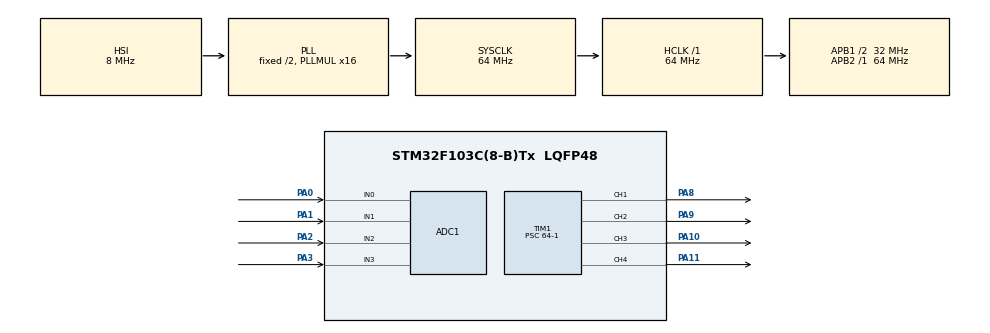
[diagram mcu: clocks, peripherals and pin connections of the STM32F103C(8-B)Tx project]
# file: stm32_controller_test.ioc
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ADC1.Channel-0\#ChannelRegularConversion=ADC_CHANNEL_0
ADC1.Channel-1\#ChannelRegularConversion=ADC_CHANNEL_1
ADC1.Channel-2\#ChannelRegularConversion=ADC_CHANNEL_2
ADC1.Channel-3\#ChannelRegularConversion=ADC_CHANNEL_3
ADC1.NbrOfConversion=4
ADC1.NbrOfConversionFlag=1
ADC1.Rank-0\#ChannelRegularConversion=1
ADC1.Rank-1\#ChannelRegularConversion=2
ADC1.Rank-2\#ChannelRegularConversion=3
ADC1.Rank-3\#ChannelRegularConversion=4
ADC1.SamplingTime-0\#ChannelRegularConversion=ADC_SAMPLETIME_1CYCLE_5
ADC1.SamplingTime-1\#ChannelRegularConversion=ADC_SAMPLETIME_1CYCLE_5
ADC1.SamplingTime-2\#ChannelRegularConversion=ADC_SAMPLETIME_1CYCLE_5
ADC1.SamplingTime-3\#ChannelRegularConversion=ADC_SAMPLETIME_1CYCLE_5
ADC1.master=1
Dma.ADC1.0.Direction=DMA_PERIPH_TO_MEMORY
Dma.ADC1.0.Instance=DMA1_Channel1
Dma.ADC1.0.MemDataAlignment=DMA_MDATAALIGN_HALFWORD
Dma.ADC1.0.MemInc=DMA_MINC_ENABLE
Dma.ADC1.0.Mode=DMA_CIRCULAR
Dma.ADC1.0.PeriphDataAlignment=DMA_PDATAALIGN_HALFWORD
Dma.ADC1.0.PeriphInc=DMA_PINC_DISABLE
Dma.ADC1.0.Priority=DMA_PRIORITY_LOW
Dma.Request0=ADC1
Mcu.Family=STM32F1
Mcu.Name=STM32F103C(8-B)Tx
Mcu.Package=LQFP48
NVIC.DMA1_Channel1_IRQn=true\:0\:0\:false\:false\:true\:false\:true\:true
NVIC.PriorityGroup=NVIC_PRIORITYGROUP_4
PA0-WKUP.Signal=ADCx_IN0
PA1.Signal=ADCx_IN1
PA10.Signal=S_TIM1_CH3
PA11.Signal=S_TIM1_CH4
PA13.Mode=Serial_Wire
PA13.Signal=SYS_JTMS-SWDIO
PA14.Mode=Serial_Wire
PA14.Signal=SYS_JTCK-SWCLK
PA2.Signal=ADCx_IN2
PA3.Signal=ADCx_IN3
PA8.Signal=S_TIM1_CH1
PA9.Signal=S_TIM1_CH2
ProjectManager.HeapSize=0x200
ProjectManager.StackSize=0x400
ProjectManager.TargetToolchain=MDK-ARM V5.32
RCC.ADCPresc=RCC_ADCPCLK2_DIV8
RCC.AHBFreq_Value=64000000
RCC.APB1CLKDivider=RCC_HCLK_DIV2
RCC.APB1Freq_Value=32000000
RCC.APB1TimFreq_Value=64000000
RCC.APB2Freq_Value=64000000
RCC.APB2TimFreq_Value=64000000
RCC.HCLKFreq_Value=64000000
RCC.PLLMUL=RCC_PLL_MUL16
RCC.SYSCLKFreq_VALUE=64000000
RCC.SYSCLKSource=RCC_SYSCLKSOURCE_PLLCLK
RCC.USBFreq_Value=64000000
SH.ADCx_IN0.0=ADC1_IN0,IN0
SH.ADCx_IN1.0=ADC1_IN1,IN1
SH.ADCx_IN2.0=ADC1_IN2,IN2
SH.ADCx_IN3.0=ADC1_IN3,IN3
SH.S_TIM1_CH1.0=TIM1_CH1,PWM Generation1 CH1
SH.S_TIM1_CH2.0=TIM1_CH2,PWM Generation2 CH2
SH.S_TIM1_CH3.0=TIM1_CH3,PWM Generation3 CH3
SH.S_TIM1_CH4.0=TIM1_CH4,PWM Generation4 CH4
TIM1.Channel-PWM\ Generation1\ CH1=TIM_CHANNEL_1
TIM1.Channel-PWM\ Generation2\ CH2=TIM_CHANNEL_2
TIM1.Channel-PWM\ Generation3\ CH3=TIM_CHANNEL_3
TIM1.Channel-PWM\ Generation4\ CH4=TIM_CHANNEL_4
TIM1.Prescaler=64-1
VP_TIM1_VS_ClockSourceINT.Mode=Internal
board=custom

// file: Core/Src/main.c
/* USER CODE BEGIN Header */
/**
  ******************************************************************************
  * @file           : main.c
  * @brief          : Main program body
  ******************************************************************************
  * @attention
  *
  * Copyright (c) 2025 STMicroelectronics.
  * All rights reserved.
  *
  * This software is licensed under terms that can be found in the LICENSE file
  * in the root directory of this software component.
  * If no LICENSE file comes with this software, it is provided AS-IS.
  *
  ******************************************************************************
  */
/* USER CODE END Header */
#include "main.h"

ADC_HandleTypeDef hadc1;
DMA_HandleTypeDef hdma_adc1;

TIM_HandleTypeDef htim1;

void SystemClock_Config(void);
static void MX_GPIO_Init(void);
static void MX_DMA_Init(void);
static void MX_ADC1_Init(void);
static void MX_TIM1_Init(void);

/* USER CODE BEGIN 0 */
#define ADC_BUFF_LEN 4
uint16_t adc_buffer[ADC_BUFF_LEN];

extern ADC_HandleTypeDef hadc1;
extern TIM_HandleTypeDef htim2;

void HAL_ADC_ConvCpltCallback(ADC_HandleTypeDef* hadc) {
    // Callback không c?n thi?t khi dùng Circular, x? lý ? while(1)
}

void read_controller_start() {
		HAL_ADCEx_Calibration_Start(&hadc1);
    HAL_ADC_Start_DMA(&hadc1, (uint32_t*)adc_buffer, ADC_BUFF_LEN);
    HAL_TIM_PWM_Start(&htim1, TIM_CHANNEL_1); // B?t d?u PWM
    // L?p n?u b?n dùng thêm TIM_CHANNEL_2,3,4
}
/* USER CODE END 0 */

int main(void)
{

  /* MCU Configuration--------------------------------------------------------*/

  /* Reset of all peripherals, Initializes the Flash interface and the Systick. */
  HAL_Init();

  /* Configure the system clock */
  SystemClock_Config();

  /* Initialize all configured peripherals */
  MX_GPIO_Init();
  MX_DMA_Init();
  MX_ADC1_Init();
  MX_TIM1_Init();
  /* USER CODE BEGIN 2 */
	read_controller_start();
  /* USER CODE END 2 */

  /* Infinite loop */
  while (1)
  {

    uint16_t ch1 = adc_buffer[0];
		uint16_t ch2 = adc_buffer[1];
		uint16_t ch3 = adc_buffer[2];
		uint16_t ch4 = adc_buffer[3];

    uint16_t pwm_ch1 = 1000 + ((ch1 * 1000) / 4095);
		uint16_t pwm_ch2 = 1000 + ((ch2 * 1000) / 4095);
		uint16_t pwm_ch3 = 1000 + ((ch3 * 1000) / 4095);
		uint16_t pwm_ch4 = 1000 + ((ch4 * 1000) / 4095);

    __HAL_TIM_SET_COMPARE(&htim1, TIM_CHANNEL_1, pwm_ch1);
		__HAL_TIM_SET_COMPARE(&htim1, TIM_CHANNEL_2, pwm_ch2);
		__HAL_TIM_SET_COMPARE(&htim1, TIM_CHANNEL_3, pwm_ch3);
		__HAL_TIM_SET_COMPARE(&htim1, TIM_CHANNEL_4, pwm_ch4);

  }
}

void SystemClock_Config(void)
{
  RCC_OscInitTypeDef RCC_OscInitStruct = {0};
  RCC_ClkInitTypeDef RCC_ClkInitStruct = {0};
  RCC_PeriphCLKInitTypeDef PeriphClkInit = {0};

  /** Initializes the RCC Oscillators according to the specified parameters
  * in the RCC_OscInitTypeDef structure.
  */
  RCC_OscInitStruct.OscillatorType = RCC_OSCILLATORTYPE_HSI;
  RCC_OscInitStruct.HSIState = RCC_HSI_ON;
  RCC_OscInitStruct.HSICalibrationValue = RCC_HSICALIBRATION_DEFAULT;
  RCC_OscInitStruct.PLL.PLLState = RCC_PLL_ON;
  RCC_OscInitStruct.PLL.PLLSource = RCC_PLLSOURCE_HSI_DIV2;
  RCC_OscInitStruct.PLL.PLLMUL = RCC_PLL_MUL16;
  if (HAL_RCC_OscConfig(&RCC_OscInitStruct) != HAL_OK)
  {
    Error_Handler();
  }

  /** Initializes the CPU, AHB and APB buses clocks
  */
  RCC_ClkInitStruct.ClockType = RCC_CLOCKTYPE_HCLK|RCC_CLOCKTYPE_SYSCLK
                              |RCC_CLOCKTYPE_PCLK1|RCC_CLOCKTYPE_PCLK2;
  RCC_ClkInitStruct.SYSCLKSource = RCC_SYSCLKSOURCE_PLLCLK;
  RCC_ClkInitStruct.AHBCLKDivider = RCC_SYSCLK_DIV1;
  RCC_ClkInitStruct.APB1CLKDivider = RCC_HCLK_DIV2;
  RCC_ClkInitStruct.APB2CLKDivider = RCC_HCLK_DIV1;

  if (HAL_RCC_ClockConfig(&RCC_ClkInitStruct, FLASH_LATENCY_2) != HAL_OK)
  {
    Error_Handler();
  }
  PeriphClkInit.PeriphClockSelection = RCC_PERIPHCLK_ADC;
  PeriphClkInit.AdcClockSelection = RCC_ADCPCLK2_DIV8;
  if (HAL_RCCEx_PeriphCLKConfig(&PeriphClkInit) != HAL_OK)
  {
    Error_Handler();
  }
}

static void MX_ADC1_Init(void)
{

  ADC_ChannelConfTypeDef sConfig = {0};

  /** Common config
  */
  hadc1.Instance = ADC1;
  hadc1.Init.ScanConvMode = ADC_SCAN_ENABLE;
  hadc1.Init.ContinuousConvMode = DISABLE;
  hadc1.Init.DiscontinuousConvMode = DISABLE;
  hadc1.Init.ExternalTrigConv = ADC_SOFTWARE_START;
  hadc1.Init.DataAlign = ADC_DATAALIGN_RIGHT;
  hadc1.Init.NbrOfConversion = 4;
  if (HAL_ADC_Init(&hadc1) != HAL_OK)
  {
    Error_Handler();
  }

  /** Configure Regular Channel
  */
  sConfig.Channel = ADC_CHANNEL_0;
  sConfig.Rank = ADC_REGULAR_RANK_1;
  sConfig.SamplingTime = ADC_SAMPLETIME_1CYCLE_5;
  if (HAL_ADC_ConfigChannel(&hadc1, &sConfig) != HAL_OK)
  {
    Error_Handler();
  }

  /** Configure Regular Channel
  */
  sConfig.Channel = ADC_CHANNEL_1;
  sConfig.Rank = ADC_REGULAR_RANK_2;
  if (HAL_ADC_ConfigChannel(&hadc1, &sConfig) != HAL_OK)
  {
    Error_Handler();
  }

  /** Configure Regular Channel
  */
  sConfig.Channel = ADC_CHANNEL_2;
  sConfig.Rank = ADC_REGULAR_RANK_3;
  if (HAL_ADC_ConfigChannel(&hadc1, &sConfig) != HAL_OK)
  {
    Error_Handler();
  }

  /** Configure Regular Channel
  */
  sConfig.Channel = ADC_CHANNEL_3;
  sConfig.Rank = ADC_REGULAR_RANK_4;
  if (HAL_ADC_ConfigChannel(&hadc1, &sConfig) != HAL_OK)
  {
    Error_Handler();
  }

}

static void MX_TIM1_Init(void)
{

  TIM_ClockConfigTypeDef sClockSourceConfig = {0};
  TIM_MasterConfigTypeDef sMasterConfig = {0};
  TIM_OC_InitTypeDef sConfigOC = {0};
  TIM_BreakDeadTimeConfigTypeDef sBreakDeadTimeConfig = {0};

  htim1.Instance = TIM1;
  htim1.Init.Prescaler = 64-1;
  htim1.Init.CounterMode = TIM_COUNTERMODE_UP;
  htim1.Init.Period = 65535;
  htim1.Init.ClockDivision = TIM_CLOCKDIVISION_DIV1;
  htim1.Init.RepetitionCounter = 0;
  htim1.Init.AutoReloadPreload = TIM_AUTORELOAD_PRELOAD_DISABLE;
  if (HAL_TIM_Base_Init(&htim1) != HAL_OK)
  {
    Error_Handler();
  }
  sClockSourceConfig.ClockSource = TIM_CLOCKSOURCE_INTERNAL;
  if (HAL_TIM_ConfigClockSource(&htim1, &sClockSourceConfig) != HAL_OK)
  {
    Error_Handler();
  }
  if (HAL_TIM_PWM_Init(&htim1) != HAL_OK)
  {
    Error_Handler();
  }
  sMasterConfig.MasterOutputTrigger = TIM_TRGO_RESET;
  sMasterConfig.MasterSlaveMode = TIM_MASTERSLAVEMODE_DISABLE;
  if (HAL_TIMEx_MasterConfigSynchronization(&htim1, &sMasterConfig) != HAL_OK)
  {
    Error_Handler();
  }
  sConfigOC.OCMode = TIM_OCMODE_PWM1;
  sConfigOC.Pulse = 0;
  sConfigOC.OCPolarity = TIM_OCPOLARITY_HIGH;
  sConfigOC.OCNPolarity = TIM_OCNPOLARITY_HIGH;
  sConfigOC.OCFastMode = TIM_OCFAST_DISABLE;
  sConfigOC.OCIdleState = TIM_OCIDLESTATE_RESET;
  sConfigOC.OCNIdleState = TIM_OCNIDLESTATE_RESET;
  if (HAL_TIM_PWM_ConfigChannel(&htim1, &sConfigOC, TIM_CHANNEL_1) != HAL_OK)
  {
    Error_Handler();
  }
  if (HAL_TIM_PWM_ConfigChannel(&htim1, &sConfigOC, TIM_CHANNEL_2) != HAL_OK)
  {
    Error_Handler();
  }
  if (HAL_TIM_PWM_ConfigChannel(&htim1, &sConfigOC, TIM_CHANNEL_3) != HAL_OK)
  {
    Error_Handler();
  }
  if (HAL_TIM_PWM_ConfigChannel(&htim1, &sConfigOC, TIM_CHANNEL_4) != HAL_OK)
  {
    Error_Handler();
  }
  sBreakDeadTimeConfig.OffStateRunMode = TIM_OSSR_DISABLE;
  sBreakDeadTimeConfig.OffStateIDLEMode = TIM_OSSI_DISABLE;
  sBreakDeadTimeConfig.LockLevel = TIM_LOCKLEVEL_OFF;
  sBreakDeadTimeConfig.DeadTime = 0;
  sBreakDeadTimeConfig.BreakState = TIM_BREAK_DISABLE;
  sBreakDeadTimeConfig.BreakPolarity = TIM_BREAKPOLARITY_HIGH;
  sBreakDeadTimeConfig.AutomaticOutput = TIM_AUTOMATICOUTPUT_DISABLE;
  if (HAL_TIMEx_ConfigBreakDeadTime(&htim1, &sBreakDeadTimeConfig) != HAL_OK)
  {
    Error_Handler();
  }
  HAL_TIM_MspPostInit(&htim1);

}

static void MX_DMA_Init(void)
{

  /* DMA controller clock enable */
  __HAL_RCC_DMA1_CLK_ENABLE();

  /* DMA interrupt init */
  /* DMA1_Channel1_IRQn interrupt configuration */
  HAL_NVIC_SetPriority(DMA1_Channel1_IRQn, 0, 0);
  HAL_NVIC_EnableIRQ(DMA1_Channel1_IRQn);

}

static void MX_GPIO_Init(void)
{

  /* GPIO Ports Clock Enable */
  __HAL_RCC_GPIOA_CLK_ENABLE();

}

void Error_Handler(void)
{
  __disable_irq();
  while (1)
  {
  }
}
